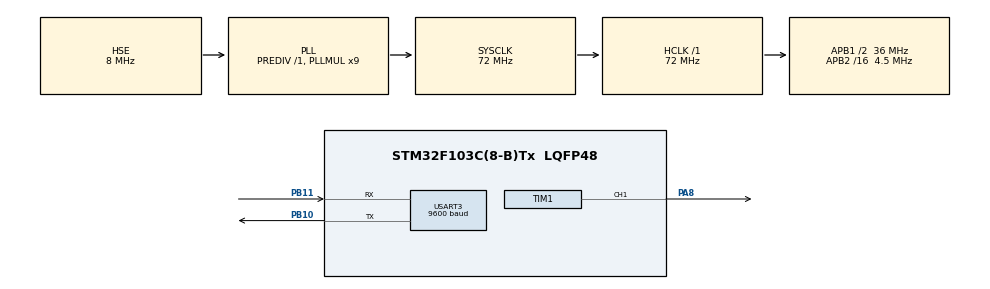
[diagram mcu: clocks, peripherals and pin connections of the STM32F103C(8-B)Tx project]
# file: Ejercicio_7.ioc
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Mcu.Family=STM32F1
Mcu.Name=STM32F103C(8-B)Tx
Mcu.Package=LQFP48
NVIC.PriorityGroup=NVIC_PRIORITYGROUP_4
NVIC.USART3_IRQn=true\:0\:0\:false\:false\:true\:true\:true\:true
PA13.Mode=Serial_Wire
PA13.Signal=SYS_JTMS-SWDIO
PA14.Mode=Serial_Wire
PA14.Signal=SYS_JTCK-SWCLK
PA8.Signal=S_TIM1_CH1
PB10.Mode=Asynchronous
PB10.Signal=USART3_TX
PB11.Mode=Asynchronous
PB11.Signal=USART3_RX
PD0-OSC_IN.Mode=HSE-External-Oscillator
PD0-OSC_IN.Signal=RCC_OSC_IN
PD1-OSC_OUT.Mode=HSE-External-Oscillator
PD1-OSC_OUT.Signal=RCC_OSC_OUT
ProjectManager.HeapSize=0x200
ProjectManager.StackSize=0x400
ProjectManager.TargetToolchain=STM32CubeIDE
RCC.AHBFreq_Value=72000000
RCC.APB1CLKDivider=RCC_HCLK_DIV2
RCC.APB1Freq_Value=36000000
RCC.APB1TimFreq_Value=72000000
RCC.APB2CLKDivider=RCC_HCLK_DIV16
RCC.APB2Freq_Value=4500000
RCC.APB2TimFreq_Value=9000000
RCC.HCLKFreq_Value=72000000
RCC.PLLMUL=RCC_PLL_MUL9
RCC.PLLSourceVirtual=RCC_PLLSOURCE_HSE
RCC.SYSCLKFreq_VALUE=72000000
RCC.SYSCLKSource=RCC_SYSCLKSOURCE_PLLCLK
RCC.USBFreq_Value=72000000
SH.S_TIM1_CH1.0=TIM1_CH1,PWM Generation1 CH1
TIM1.AutoReloadPreload=TIM_AUTORELOAD_PRELOAD_ENABLE
TIM1.Channel-PWM\ Generation1\ CH1=TIM_CHANNEL_1
TIM1.Period=1000
TIM1.Prescaler=180-1
USART3.BaudRate=9600
USART3.VirtualMode=VM_ASYNC
VP_TIM1_VS_ClockSourceINT.Mode=Internal
board=custom

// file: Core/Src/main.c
/* USER CODE BEGIN Header */
/**
  ******************************************************************************
  * @file           : main.c
  * @brief          : Main program body
  ******************************************************************************
  * @attention
  *
  * Copyright (c) 2024 STMicroelectronics.
  * All rights reserved.
  *
  * This software is licensed under terms that can be found in the LICENSE file
  * in the root directory of this software component.
  * If no LICENSE file comes with this software, it is provided AS-IS.
  *
  ******************************************************************************
  */
/* USER CODE END Header */
#include "main.h"
#include "tim.h"
#include "usart.h"
#include "gpio.h"

/* USER CODE BEGIN Includes */
#include <stdio.h>
#include <string.h>
#include "itoa.h"
#include <stdlib.h>
/* USER CODE END Includes */

/* USER CODE BEGIN PV */
 //RX
 uint8_t rx_dato = 0;
 //PWM
 uint16_t datoRX_convercion_duty_cycle = 0;

/* USER CODE END PV */

void SystemClock_Config(void);

/* USER CODE BEGIN 0 */

// funcion para habilitar "printf"
int __io_putchar(int ch)
{
	HAL_UART_Transmit(&huart3, (uint8_t *)&ch, 1, 100);
	return ch;
}

//La función map sirve para convertir números de un rango a otro
uint16_t map( uint16_t x, uint16_t min_int, uint16_t max_int, uint16_t min_out, uint16_t max_out )
{
	uint16_t resultado;
	resultado = (x - min_int) * (max_out - min_out) / (max_int - min_int) + min_out;
    return resultado;
}
/* USER CODE END 0 */

int main(void)
{

  /* MCU Configuration--------------------------------------------------------*/

  /* Reset of all peripherals, Initializes the Flash interface and the Systick. */
  HAL_Init();

  /* Configure the system clock */
  SystemClock_Config();

  /* Initialize all configured peripherals */
  MX_GPIO_Init();
  MX_USART3_UART_Init();
  MX_TIM1_Init();
  /* USER CODE BEGIN 2 */
  HAL_TIM_PWM_Start(&htim1, TIM_CHANNEL_1);
  HAL_UART_Receive_IT(&huart3, &rx_dato, 3);
  /* USER CODE END 2 */

  /* Infinite loop */
  /* USER CODE BEGIN WHILE */
  while (1)
  {
	  TIM1->CCR1 = datoRX_convercion_duty_cycle;//ciclo de trabajo del motor dc que va de 0 a 1000
	  printf("Duty Cycle: %d\n\r", rx_dato);
    /* USER CODE END WHILE */

  }
}

void SystemClock_Config(void)
{
  RCC_OscInitTypeDef RCC_OscInitStruct = {0};
  RCC_ClkInitTypeDef RCC_ClkInitStruct = {0};

  /** Initializes the RCC Oscillators according to the specified parameters
  * in the RCC_OscInitTypeDef structure.
  */
  RCC_OscInitStruct.OscillatorType = RCC_OSCILLATORTYPE_HSE;
  RCC_OscInitStruct.HSEState = RCC_HSE_ON;
  RCC_OscInitStruct.HSEPredivValue = RCC_HSE_PREDIV_DIV1;
  RCC_OscInitStruct.HSIState = RCC_HSI_ON;
  RCC_OscInitStruct.PLL.PLLState = RCC_PLL_ON;
  RCC_OscInitStruct.PLL.PLLSource = RCC_PLLSOURCE_HSE;
  RCC_OscInitStruct.PLL.PLLMUL = RCC_PLL_MUL9;
  if (HAL_RCC_OscConfig(&RCC_OscInitStruct) != HAL_OK)
  {
    Error_Handler();
  }

  /** Initializes the CPU, AHB and APB buses clocks
  */
  RCC_ClkInitStruct.ClockType = RCC_CLOCKTYPE_HCLK|RCC_CLOCKTYPE_SYSCLK
                              |RCC_CLOCKTYPE_PCLK1|RCC_CLOCKTYPE_PCLK2;
  RCC_ClkInitStruct.SYSCLKSource = RCC_SYSCLKSOURCE_PLLCLK;
  RCC_ClkInitStruct.AHBCLKDivider = RCC_SYSCLK_DIV1;
  RCC_ClkInitStruct.APB1CLKDivider = RCC_HCLK_DIV2;
  RCC_ClkInitStruct.APB2CLKDivider = RCC_HCLK_DIV16;

  if (HAL_RCC_ClockConfig(&RCC_ClkInitStruct, FLASH_LATENCY_2) != HAL_OK)
  {
    Error_Handler();
  }
}

/* USER CODE BEGIN 4 */
void HAL_UART_RxCpltCallback(UART_HandleTypeDef *huart)
{
	if(huart->Instance == USART3)
	{
		//convertimos el dato obtenido del RX a duty cycle
		datoRX_convercion_duty_cycle = map(rx_dato, 0, 100, 0, 1000);
		HAL_UART_Receive_IT(&huart3, &rx_dato, 3);
	}
}

/* USER CODE END 4 */

void Error_Handler(void)
{
  __disable_irq();
  while (1)
  {
  }
}
